# HSM_SOC_CTRL register map
Vendor: Texas Instruments
Peripheral module from a debugger description file (folder awr29xx).
Registers are 32-bit, read-write, no defined reset value unless marked. A register's access mark holds for its fields unless they carry their own. Offsets are as the file gives them; lines under a group give offsets from that group; [hi:lo] are bit positions; {n}, {i} and the like mark numbered series; 'fields as' and 'values as' point back to an identical list; <NAME> marks a mode.

## HSM_SOC_CTRL
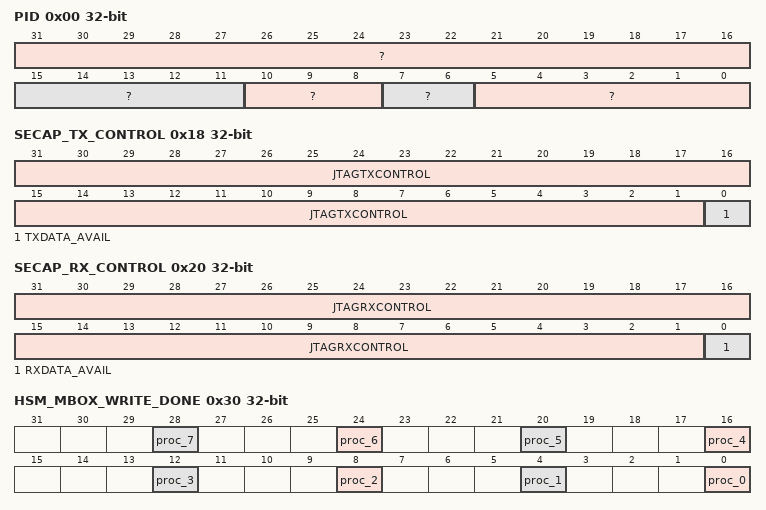
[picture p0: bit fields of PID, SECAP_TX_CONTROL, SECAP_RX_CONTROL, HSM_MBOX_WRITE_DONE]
0x00 PID ro
  [31:16] ?, [15:11] ?, [10:8] ?, [7:6] ?, [5:0] ?
0x04 HW_REG0
  [31:0] hwreg0 — Reserved for HW R&D
0x08 HW_REG1
  [31:0] hwreg1 — Reserved for HW R&D
0x0C PREVIOUS_NAME
  [31:0] hwreg2 — Reserved for HW R&D
0x10 HW_REG3
  [31:0] hwreg3 — Reserved for HW R&D
0x14 SECAP_TX_DATA ro
  [31:0] JTAGTXDATA — This register is used to pass data to the system security logic. The data is transmit from the external JTAG interface and hence is the Rx path for the SECAP interface.
0x18 SECAP_TX_CONTROL ro
  [31:1] JTAGTXCONTROL — This register is provides the handshake for the JTAGTXDATA Register and can also be used to pass control information to the system security logic.
  [0] TXDATA_AVAIL — Tx Interrupt to indicate avaliablity of TXDATA . 1 - TXDATA available ; 0 - TXDATA not available
0x1C SECAP_RX_DATA
  [31:0] JTAGRXDATA — This register is used to pass data from the system security logic. The data is transmit from the SECAP interface to external JTAG interface and hence is the Tx path for the SECAP interface.
0x20 SECAP_RX_CONTROL access per field
  [31:1] JTAGRXCONTROL rw — This register is provides the handshake for the JTAGRXDATA Register and can also be used to pass control information from the system security logic
  [0] RXDATA_AVAIL ro — Tx Interrupt to indicate avaliablity of RXDATA . 1 - RXDATA available ; 0 - RXDATA not available
0x24 HSM_MBOX_MEMINIT_START
  [0] hsm_mbox_meminit_start — Write pulse bit field:#br#Start Memory intialization of Param memory.Write 0x1 to start memory initilization.Write 0x0 after ensuring Memory intilization is in progress or has completed.Before starting new initilzation sequence ensure that there is no initilization sequence is in progress (ie MEMINIT_STATUS should be 0x0) and clear any previouls complettion status(ie write 0x1 to clear MEMINIT_DONE)
0x28 HSM_MBOX_MEMINIT_STATUS ro
  [0] hsm_mbox_meminit_status — Status field. Read value 0x1 indicates previously triggered Memory intialization of Param memory is in progress.
0x2C HSM_MBOX_MEMINIT_DONE
  [0] hsm_mbox_meminit_done — Status field. Read value 0x1 indicates previously triggered Memory intialization of Param memory is complte.#br#Write 0x1 to clear status. Refer Memory initialization sequnce in EDMA section for more details
0x30 HSM_MBOX_WRITE_DONE
  [4n] proc_{n} (n=0..7) — Write pulse bit field:#br#This register should be written once finishing writing into the mailbox memory of processor {n}
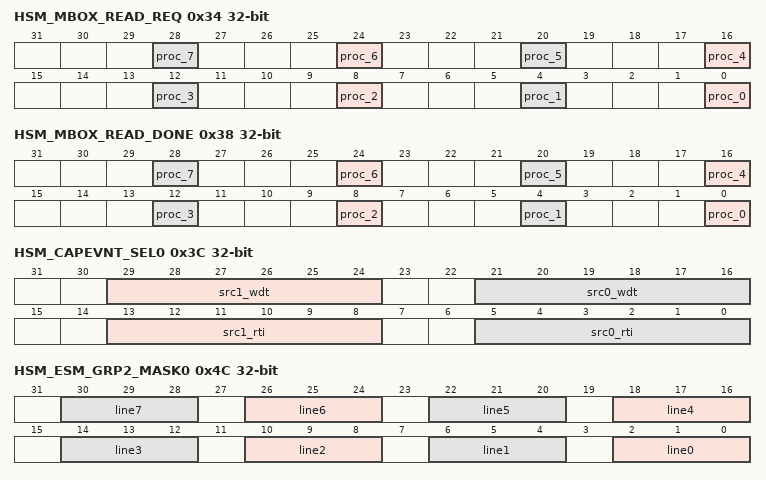
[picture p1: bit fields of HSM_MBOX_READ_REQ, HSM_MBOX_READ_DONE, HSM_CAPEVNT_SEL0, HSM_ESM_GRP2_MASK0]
0x34 HSM_MBOX_READ_REQ
  [4n] proc_{n} (n=0..7) — This is request from processor {n} to HSM. Requesting it to read from mailbox.
0x38 HSM_MBOX_READ_DONE
  [4n] proc_{n} (n=0..7) — This register should be written once finishing reading from hsm's mailbox written by proc {n}
0x3C HSM_CAPEVNT_SEL0
  [29:24] src1_wdt — Used to select one of the 64 interrupts which would go as second trigger to WDT
  [21:16] src0_wdt — Used to select one of the 64 interrupts which would go as first trigger to WDT
  [13:8] src1_rti — Used to select one of the 64 interrupts which would go as second trigger to RTI
  [5:0] src0_rti — Used to select one of the 64 interrupts which would go as first trigger to RTI
0x40 HSM_DMA_REQ
  [2:0] select — Software configration for DMA Request
0x44 HSM_IRQ_REQ
  [3:0] select — Write pulse bit field:#br#Software configration for INT Request
0x48 HSM_ESM_REQ
  [1:0] select — Software configration for ESM Request
0x4C HSM_ESM_GRP2_MASK0
  [4n+2:4n] line{n} (n=0..7) — Writing 3'b111 will un-mask the ESM error for the respective group and line
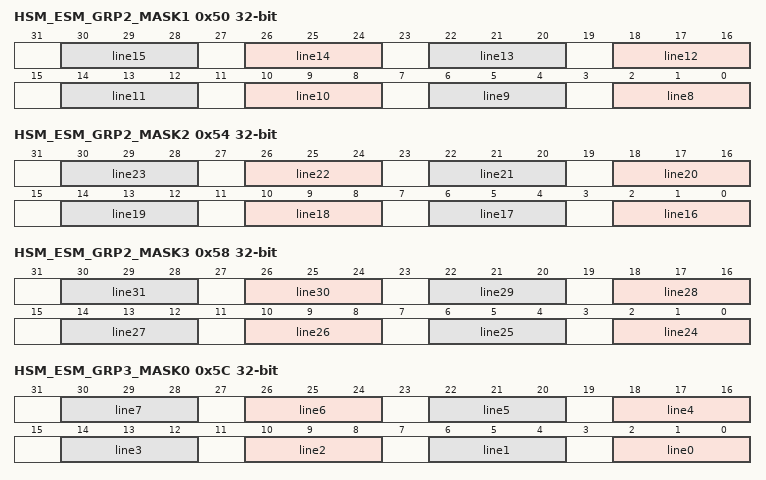
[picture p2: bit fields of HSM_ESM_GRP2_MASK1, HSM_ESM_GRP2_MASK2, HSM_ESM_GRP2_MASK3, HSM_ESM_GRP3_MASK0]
0x50 HSM_ESM_GRP2_MASK1
  [4n-30:4n-32] line{n} (n=8..15) — Writing 3'b111 will un-mask the ESM error for the respective group and line
0x54 HSM_ESM_GRP2_MASK2
  [4n-62:4n-64] line{n} (n=16..23) — Writing 3'b111 will un-mask the ESM error for the respective group and line
0x58 HSM_ESM_GRP2_MASK3
  [4n-94:4n-96] line{n} (n=24..31) — Writing 3'b111 will un-mask the ESM error for the respective group and line
0x5C HSM_ESM_GRP3_MASK0
  fields as HSM_ESM_GRP2_MASK0
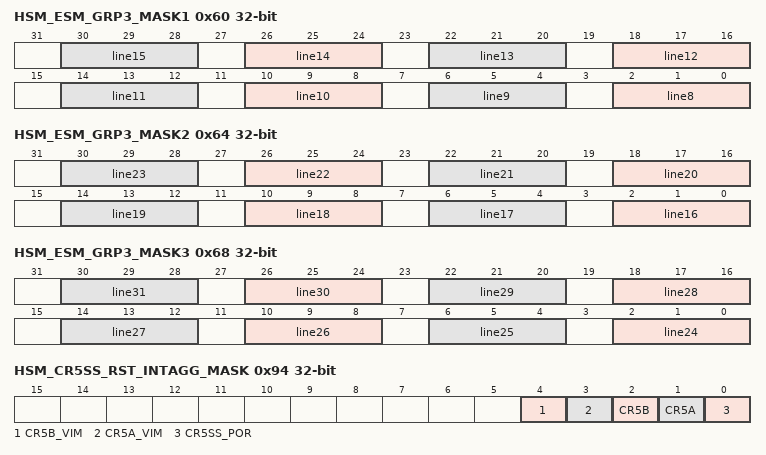
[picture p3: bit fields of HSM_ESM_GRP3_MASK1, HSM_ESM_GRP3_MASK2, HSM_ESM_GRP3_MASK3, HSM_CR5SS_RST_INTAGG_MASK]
0x60 HSM_ESM_GRP3_MASK1
  fields as HSM_ESM_GRP2_MASK1
0x64 HSM_ESM_GRP3_MASK2
  fields as HSM_ESM_GRP2_MASK2
0x68 HSM_ESM_GRP3_MASK3
  fields as HSM_ESM_GRP2_MASK3
0x6C HSM_MSS_RST_CAUSE ro
  [15:0] status — Indicates the Reset Cause of MSS#br#Has the status because of which reset has happened. Bit0: por_reset Bit1: warm reset Bit2: stc reset Bit3: mmr_reset for resetting CPU0 and vim0 Bit4: mmr_reset for resetting CPU1 and VIM1 Bit5: mmr_reset for resettng CPU0 only Bit6: mmr_reset for resetting CPU1 only #br#Bit7: reset caused becasue for dbg_rst_req by CPU0 Bit8: reset caused becasue for dbg_rst_req by CPU0 Bit9: reset caused by the reset_fsm
0x70 HSM_MSS_RST_CAUSE_CLR
  [2:0] clear — Write pulse bit field:#br#Writing '111' will clear the HSM_MSS_RST_CAUSE_STATUS field
{0x74+4i} HSM_SECURE_BOOT_INFO_REG{i} (i=0..7)
  [31:0] reg — Secure Boot Status Registers
0x94 HSM_CR5SS_RST_INTAGG_MASK
  [4] CR5B_VIM — Writing '1' will mask the respective MSS R5SS RST interrupt line
  [3] CR5A_VIM — Writing '1' will mask the respective MSS R5SS RST interrupt line
  [2] CR5B — Writing '1' will mask the respective MSS R5SS RST interrupt line
  [1] CR5A — Writing '1' will mask the respective MSS R5SS RST interrupt line
  [0] CR5SS_POR — Writing '1' will mask the respective MSS R5SS RST interrupt line
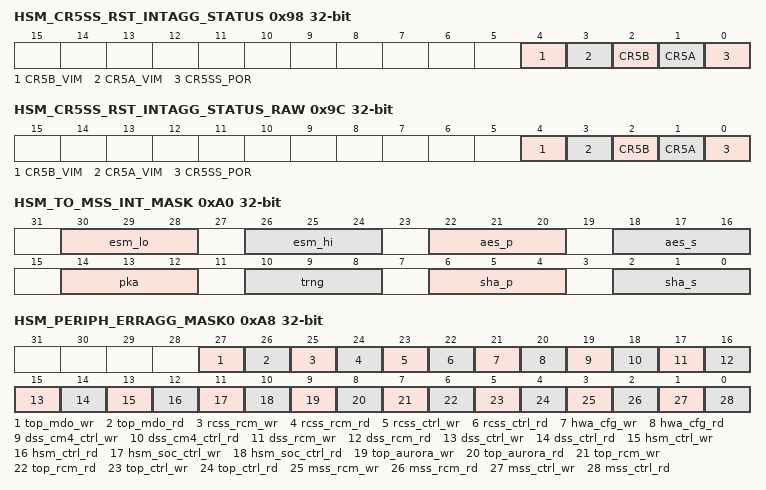
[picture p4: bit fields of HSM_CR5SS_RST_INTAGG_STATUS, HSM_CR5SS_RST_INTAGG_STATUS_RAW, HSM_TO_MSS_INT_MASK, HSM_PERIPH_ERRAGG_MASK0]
0x98 HSM_CR5SS_RST_INTAGG_STATUS
  [4] CR5B_VIM — Indicates the post mask status of the respective MSS R5SS RST interrupt line
  [3] CR5A_VIM — Indicates the post mask status of the respective MSS R5SS RST interrupt line
  [2] CR5B — Indicates the post mask status of the respective MSS R5SS RST interrupt line
  [1] CR5A — Indicates the post mask status of the respective MSS R5SS RST interrupt line
  [0] CR5SS_POR — Indicates the post mask status of the respective MSS R5SS RST interrupt line
0x9C HSM_CR5SS_RST_INTAGG_STATUS_RAW
  [4] CR5B_VIM — Indicates the pre mask status of the respective MSS R5SS RST interrupt line
  [3] CR5A_VIM — Indicates the pre mask status of the respective MSS R5SS RST interrupt line
  [2] CR5B — Indicates the pre mask status of the respective MSS R5SS RST interrupt line
  [1] CR5A — Indicates the pre mask status of the respective MSS R5SS RST interrupt line
  [0] CR5SS_POR — Indicates the pre mask status of the respective MSS R5SS RST interrupt line
0xA0 HSM_TO_MSS_INT_MASK
  [30:28] esm_lo — Writing 3'b111 will un-mask the respective HSM Interrupt line to MSS
  [26:24] esm_hi — Writing 3'b111 will un-mask the respective HSM Interrupt line to MSS
  [22:20] aes_p — Writing 3'b111 will un-mask the respective HSM Interrupt line to MSS
  [18:16] aes_s — Writing 3'b111 will un-mask the respective HSM Interrupt line to MSS
  [14:12] pka — Writing 3'b111 will un-mask the respective HSM Interrupt line to MSS
  [10:8] trng — Writing 3'b111 will un-mask the respective HSM Interrupt line to MSS
  [6:4] sha_p — Writing 3'b111 will un-mask the respective HSM Interrupt line to MSS
  [2:0] sha_s — Writing 3'b111 will un-mask the respective HSM Interrupt line to MSS
0xA4 HSM_WDT_RST_CONFIG
  [2:0] enable — Writing 3'b111 will enable WDT Reset Propogation
0xA8 HSM_PERIPH_ERRAGG_MASK0
  [27] top_mdo_wr — Writing '1' will mask the respective peripheral error line
  [26] top_mdo_rd — Writing '1' will mask the respective peripheral error line
  [25] rcss_rcm_wr — Writing '1' will mask the respective peripheral error line
  [24] rcss_rcm_rd — Writing '1' will mask the respective peripheral error line
  [23] rcss_ctrl_wr — Writing '1' will mask the respective peripheral error line
  [22] rcss_ctrl_rd — Writing '1' will mask the respective peripheral error line
  [21] hwa_cfg_wr — Writing '1' will mask the respective peripheral error line
  [20] hwa_cfg_rd — Writing '1' will mask the respective peripheral error line
  [19] dss_cm4_ctrl_wr — Writing '1' will mask the respective peripheral error line
  [18] dss_cm4_ctrl_rd — Writing '1' will mask the respective peripheral error line
  [17] dss_rcm_wr — Writing '1' will mask the respective peripheral error line
  [16] dss_rcm_rd — Writing '1' will mask the respective peripheral error line
  [15] dss_ctrl_wr — Writing '1' will mask the respective peripheral error line
  [14] dss_ctrl_rd — Writing '1' will mask the respective peripheral error line
  [13] hsm_ctrl_wr — Writing '1' will mask the respective peripheral error line
  [12] hsm_ctrl_rd — Writing '1' will mask the respective peripheral error line
  [11] hsm_soc_ctrl_wr — Writing '1' will mask the respective peripheral error line
  [10] hsm_soc_ctrl_rd — Writing '1' will mask the respective peripheral error line
  [9] top_aurora_wr — Writing '1' will mask the respective peripheral error line
  [8] top_aurora_rd — Writing '1' will mask the respective peripheral error line
  [7] top_rcm_wr — Writing '1' will mask the respective peripheral error line
  [6] top_rcm_rd — Writing '1' will mask the respective peripheral error line
  [5] top_ctrl_wr — Writing '1' will mask the respective peripheral error line
  [4] top_ctrl_rd — Writing '1' will mask the respective peripheral error line
  [3] mss_rcm_wr — Writing '1' will mask the respective peripheral error line
  [2] mss_rcm_rd — Writing '1' will mask the respective peripheral error line
  [1] mss_ctrl_wr — Writing '1' will mask the respective peripheral error line
  [0] mss_ctrl_rd — Writing '1' will mask the respective peripheral error line
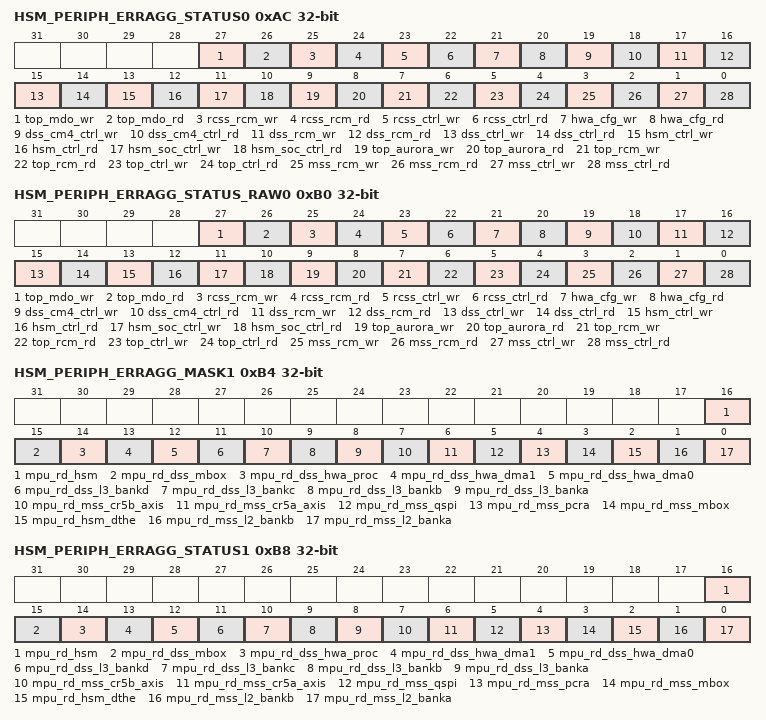
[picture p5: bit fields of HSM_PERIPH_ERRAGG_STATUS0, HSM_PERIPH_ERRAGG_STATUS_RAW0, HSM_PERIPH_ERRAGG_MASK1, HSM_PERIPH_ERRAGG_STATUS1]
0xAC HSM_PERIPH_ERRAGG_STATUS0
  [27] top_mdo_wr — Indicates the post mask status of the respective peripheral error line
  [26] top_mdo_rd — Indicates the post mask status of the respective peripheral error line
  [25] rcss_rcm_wr — Indicates the post mask status of the respective peripheral error line
  [24] rcss_rcm_rd — Indicates the post mask status of the respective peripheral error line
  [23] rcss_ctrl_wr — Indicates the post mask status of the respective peripheral error line
  [22] rcss_ctrl_rd — Indicates the post mask status of the respective peripheral error line
  [21] hwa_cfg_wr — Indicates the post mask status of the respective peripheral error line
  [20] hwa_cfg_rd — Indicates the post mask status of the respective peripheral error line
  [19] dss_cm4_ctrl_wr — Indicates the post mask status of the respective peripheral error line
  [18] dss_cm4_ctrl_rd — Indicates the post mask status of the respective peripheral error line
  [17] dss_rcm_wr — Indicates the post mask status of the respective peripheral error line
  [16] dss_rcm_rd — Indicates the post mask status of the respective peripheral error line
  [15] dss_ctrl_wr — Indicates the post mask status of the respective peripheral error line
  [14] dss_ctrl_rd — Indicates the post mask status of the respective peripheral error line
  [13] hsm_ctrl_wr — Indicates the post mask status of the respective peripheral error line
  [12] hsm_ctrl_rd — Indicates the post mask status of the respective peripheral error line
  [11] hsm_soc_ctrl_wr — Indicates the post mask status of the respective peripheral error line
  [10] hsm_soc_ctrl_rd — Indicates the post mask status of the respective peripheral error line
  [9] top_aurora_wr — Indicates the post mask status of the respective peripheral error line
  [8] top_aurora_rd — Indicates the post mask status of the respective peripheral error line
  [7] top_rcm_wr — Indicates the post mask status of the respective peripheral error line
  [6] top_rcm_rd — Indicates the post mask status of the respective peripheral error line
  [5] top_ctrl_wr — Indicates the post mask status of the respective peripheral error line
  [4] top_ctrl_rd — Indicates the post mask status of the respective peripheral error line
  [3] mss_rcm_wr — Indicates the post mask status of the respective peripheral error line
  [2] mss_rcm_rd — Indicates the post mask status of the respective peripheral error line
  [1] mss_ctrl_wr — Indicates the post mask status of the respective peripheral error line
  [0] mss_ctrl_rd — Indicates the post mask status of the respective peripheral error line
0xB0 HSM_PERIPH_ERRAGG_STATUS_RAW0
  [27] top_mdo_wr — Indicates the pre mask status of the respective peripheral error line
  [26] top_mdo_rd — Indicates the pre mask status of the respective peripheral error line
  [25] rcss_rcm_wr — Indicates the pre mask status of the respective peripheral error line
  [24] rcss_rcm_rd — Indicates the pre mask status of the respective peripheral error line
  [23] rcss_ctrl_wr — Indicates the pre mask status of the respective peripheral error line
  [22] rcss_ctrl_rd — Indicates the pre mask status of the respective peripheral error line
  [21] hwa_cfg_wr — Indicates the pre mask status of the respective peripheral error line
  [20] hwa_cfg_rd — Indicates the pre mask status of the respective peripheral error line
  [19] dss_cm4_ctrl_wr — Indicates the pre mask status of the respective peripheral error line
  [18] dss_cm4_ctrl_rd — Indicates the pre mask status of the respective peripheral error line
  [17] dss_rcm_wr — Indicates the pre mask status of the respective peripheral error line
  [16] dss_rcm_rd — Indicates the pre mask status of the respective peripheral error line
  [15] dss_ctrl_wr — Indicates the pre mask status of the respective peripheral error line
  [14] dss_ctrl_rd — Indicates the pre mask status of the respective peripheral error line
  [13] hsm_ctrl_wr — Indicates the pre mask status of the respective peripheral error line
  [12] hsm_ctrl_rd — Indicates the pre mask status of the respective peripheral error line
  [11] hsm_soc_ctrl_wr — Indicates the pre mask status of the respective peripheral error line
  [10] hsm_soc_ctrl_rd — Indicates the pre mask status of the respective peripheral error line
  [9] top_aurora_wr — Indicates the pre mask status of the respective peripheral error line
  [8] top_aurora_rd — Indicates the pre mask status of the respective peripheral error line
  [7] top_rcm_wr — Indicates the pre mask status of the respective peripheral error line
  [6] top_rcm_rd — Indicates the pre mask status of the respective peripheral error line
  [5] top_ctrl_wr — Indicates the pre mask status of the respective peripheral error line
  [4] top_ctrl_rd — Indicates the pre mask status of the respective peripheral error line
  [3] mss_rcm_wr — Indicates the pre mask status of the respective peripheral error line
  [2] mss_rcm_rd — Indicates the pre mask status of the respective peripheral error line
  [1] mss_ctrl_wr — Indicates the pre mask status of the respective peripheral error line
  [0] mss_ctrl_rd — Indicates the pre mask status of the respective peripheral error line
0xB4 HSM_PERIPH_ERRAGG_MASK1
  [16] mpu_rd_hsm — Writing '1' will mask the respective peripheral error line
  [15] mpu_rd_dss_mbox — Writing '1' will mask the respective peripheral error line
  [14] mpu_rd_dss_hwa_proc — Writing '1' will mask the respective peripheral error line
  [13] mpu_rd_dss_hwa_dma1 — Writing '1' will mask the respective peripheral error line
  [12] mpu_rd_dss_hwa_dma0 — Writing '1' will mask the respective peripheral error line
  [11] mpu_rd_dss_l3_bankd — Writing '1' will mask the respective peripheral error line
  [10] mpu_rd_dss_l3_bankc — Writing '1' will mask the respective peripheral error line
  [9] mpu_rd_dss_l3_bankb — Writing '1' will mask the respective peripheral error line
  [8] mpu_rd_dss_l3_banka — Writing '1' will mask the respective peripheral error line
  [7] mpu_rd_mss_cr5b_axis — Writing '1' will mask the respective peripheral error line
  [6] mpu_rd_mss_cr5a_axis — Writing '1' will mask the respective peripheral error line
  [5] mpu_rd_mss_qspi — Writing '1' will mask the respective peripheral error line
  [4] mpu_rd_mss_pcra — Writing '1' will mask the respective peripheral error line
  [3] mpu_rd_mss_mbox — Writing '1' will mask the respective peripheral error line
  [2] mpu_rd_hsm_dthe — Writing '1' will mask the respective peripheral error line
  [1] mpu_rd_mss_l2_bankb — Writing '1' will mask the respective peripheral error line
  [0] mpu_rd_mss_l2_banka — Writing '1' will mask the respective peripheral error line
0xB8 HSM_PERIPH_ERRAGG_STATUS1
  [16] mpu_rd_hsm — Indicates the post mask status of the respective peripheral error line
  [15] mpu_rd_dss_mbox — Indicates the post mask status of the respective peripheral error line
  [14] mpu_rd_dss_hwa_proc — Indicates the post mask status of the respective peripheral error line
  [13] mpu_rd_dss_hwa_dma1 — Indicates the post mask status of the respective peripheral error line
  [12] mpu_rd_dss_hwa_dma0 — Indicates the post mask status of the respective peripheral error line
  [11] mpu_rd_dss_l3_bankd — Indicates the post mask status of the respective peripheral error line
  [10] mpu_rd_dss_l3_bankc — Indicates the post mask status of the respective peripheral error line
  [9] mpu_rd_dss_l3_bankb — Indicates the post mask status of the respective peripheral error line
  [8] mpu_rd_dss_l3_banka — Indicates the post mask status of the respective peripheral error line
  [7] mpu_rd_mss_cr5b_axis — Indicates the post mask status of the respective peripheral error line
  [6] mpu_rd_mss_cr5a_axis — Indicates the post mask status of the respective peripheral error line
  [5] mpu_rd_mss_qspi — Indicates the post mask status of the respective peripheral error line
  [4] mpu_rd_mss_pcra — Indicates the post mask status of the respective peripheral error line
  [3] mpu_rd_mss_mbox — Indicates the post mask status of the respective peripheral error line
  [2] mpu_rd_hsm_dthe — Indicates the post mask status of the respective peripheral error line
  [1] mpu_rd_mss_l2_bankb — Indicates the post mask status of the respective peripheral error line
  [0] mpu_rd_mss_l2_banka — Indicates the post mask status of the respective peripheral error line
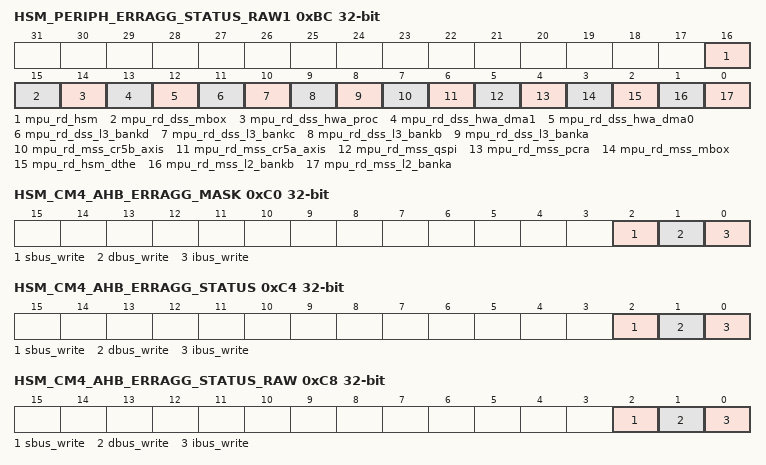
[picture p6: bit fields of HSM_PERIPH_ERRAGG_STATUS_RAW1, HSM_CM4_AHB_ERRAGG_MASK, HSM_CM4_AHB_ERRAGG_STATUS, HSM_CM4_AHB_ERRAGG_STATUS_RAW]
0xBC HSM_PERIPH_ERRAGG_STATUS_RAW1
  [16] mpu_rd_hsm — Indicates the pre mask status of the respective peripheral error line
  [15] mpu_rd_dss_mbox — Indicates the pre mask status of the respective peripheral error line
  [14] mpu_rd_dss_hwa_proc — Indicates the pre mask status of the respective peripheral error line
  [13] mpu_rd_dss_hwa_dma1 — Indicates the pre mask status of the respective peripheral error line
  [12] mpu_rd_dss_hwa_dma0 — Indicates the pre mask status of the respective peripheral error line
  [11] mpu_rd_dss_l3_bankd — Indicates the pre mask status of the respective peripheral error line
  [10] mpu_rd_dss_l3_bankc — Indicates the pre mask status of the respective peripheral error line
  [9] mpu_rd_dss_l3_bankb — Indicates the pre mask status of the respective peripheral error line
  [8] mpu_rd_dss_l3_banka — Indicates the pre mask status of the respective peripheral error line
  [7] mpu_rd_mss_cr5b_axis — Indicates the pre mask status of the respective peripheral error line
  [6] mpu_rd_mss_cr5a_axis — Indicates the pre mask status of the respective peripheral error line
  [5] mpu_rd_mss_qspi — Indicates the pre mask status of the respective peripheral error line
  [4] mpu_rd_mss_pcra — Indicates the pre mask status of the respective peripheral error line
  [3] mpu_rd_mss_mbox — Indicates the pre mask status of the respective peripheral error line
  [2] mpu_rd_hsm_dthe — Indicates the pre mask status of the respective peripheral error line
  [1] mpu_rd_mss_l2_bankb — Indicates the pre mask status of the respective peripheral error line
  [0] mpu_rd_mss_l2_banka — Indicates the pre mask status of the respective peripheral error line
0xC0 HSM_CM4_AHB_ERRAGG_MASK
  [2] sbus_write — Writing '1' will mask the respective peripheral error line
  [1] dbus_write — Writing '1' will mask the respective peripheral error line
  [0] ibus_write — Writing '1' will mask the respective peripheral error line
0xC4 HSM_CM4_AHB_ERRAGG_STATUS
  [2] sbus_write — Indicates the post mask status of the respective peripheral error line
  [1] dbus_write — Indicates the post mask status of the respective peripheral error line
  [0] ibus_write — Indicates the post mask status of the respective peripheral error line
0xC8 HSM_CM4_AHB_ERRAGG_STATUS_RAW
  [2] sbus_write — Indicates the pre mask status of the respective peripheral error line
  [1] dbus_write — Indicates the pre mask status of the respective peripheral error line
  [0] ibus_write — Indicates the pre mask status of the respective peripheral error line
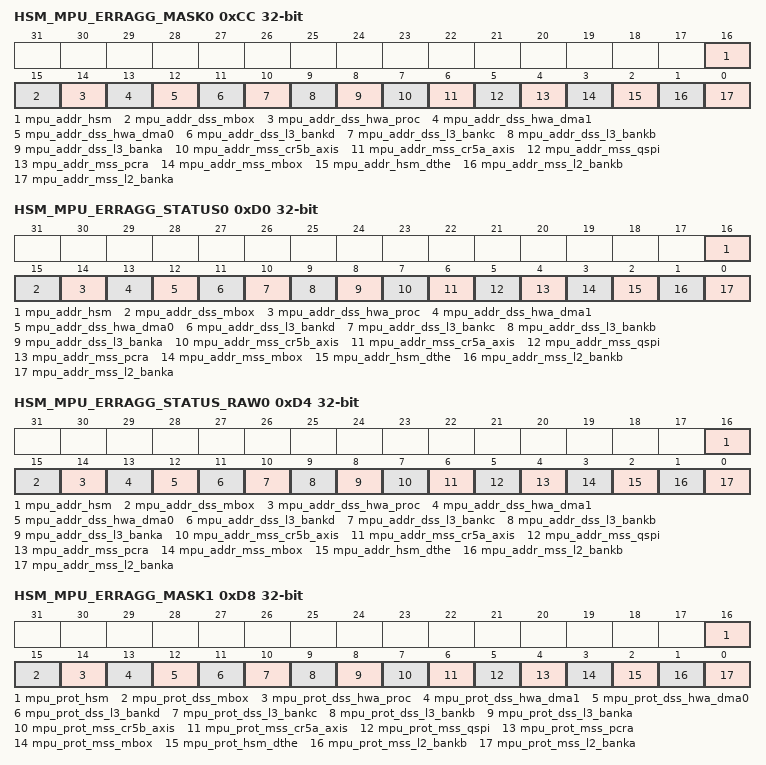
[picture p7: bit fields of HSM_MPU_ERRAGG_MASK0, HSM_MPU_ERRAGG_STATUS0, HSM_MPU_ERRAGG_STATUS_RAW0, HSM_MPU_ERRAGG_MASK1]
0xCC HSM_MPU_ERRAGG_MASK0
  [16] mpu_addr_hsm — Writing '1' will mask the respective MPU address error line
  [15] mpu_addr_dss_mbox — Writing '1' will mask the respective MPU address error line
  [14] mpu_addr_dss_hwa_proc — Writing '1' will mask the respective MPU address error line
  [13] mpu_addr_dss_hwa_dma1 — Writing '1' will mask the respective MPU address error line
  [12] mpu_addr_dss_hwa_dma0 — Writing '1' will mask the respective MPU address error line
  [11] mpu_addr_dss_l3_bankd — Writing '1' will mask the respective MPU address error line
  [10] mpu_addr_dss_l3_bankc — Writing '1' will mask the respective MPU address error line
  [9] mpu_addr_dss_l3_bankb — Writing '1' will mask the respective MPU address error line
  [8] mpu_addr_dss_l3_banka — Writing '1' will mask the respective MPU address error line
  [7] mpu_addr_mss_cr5b_axis — Writing '1' will mask the respective MPU address error line
  [6] mpu_addr_mss_cr5a_axis — Writing '1' will mask the respective MPU address error line
  [5] mpu_addr_mss_qspi — Writing '1' will mask the respective MPU address error line
  [4] mpu_addr_mss_pcra — Writing '1' will mask the respective MPU address error line
  [3] mpu_addr_mss_mbox — Writing '1' will mask the respective MPU address error line
  [2] mpu_addr_hsm_dthe — Writing '1' will mask the respective MPU address error line
  [1] mpu_addr_mss_l2_bankb — Writing '1' will mask the respective MPU address error line
  [0] mpu_addr_mss_l2_banka — Writing '1' will mask the respective MPU address error line
0xD0 HSM_MPU_ERRAGG_STATUS0
  [16] mpu_addr_hsm — Indicates the post mask status of the respective MPU address error line
  [15] mpu_addr_dss_mbox — Indicates the post mask status of the respective MPU address error line
  [14] mpu_addr_dss_hwa_proc — Indicates the post mask status of the respective MPU address error line
  [13] mpu_addr_dss_hwa_dma1 — Indicates the post mask status of the respective MPU address error line
  [12] mpu_addr_dss_hwa_dma0 — Indicates the post mask status of the respective MPU address error line
  [11] mpu_addr_dss_l3_bankd — Indicates the post mask status of the respective MPU address error line
  [10] mpu_addr_dss_l3_bankc — Indicates the post mask status of the respective MPU address error line
  [9] mpu_addr_dss_l3_bankb — Indicates the post mask status of the respective MPU address error line
  [8] mpu_addr_dss_l3_banka — Indicates the post mask status of the respective MPU address error line
  [7] mpu_addr_mss_cr5b_axis — Indicates the post mask status of the respective MPU address error line
  [6] mpu_addr_mss_cr5a_axis — Indicates the post mask status of the respective MPU address error line
  [5] mpu_addr_mss_qspi — Indicates the post mask status of the respective MPU address error line
  [4] mpu_addr_mss_pcra — Indicates the post mask status of the respective MPU address error line
  [3] mpu_addr_mss_mbox — Indicates the post mask status of the respective MPU address error line
  [2] mpu_addr_hsm_dthe — Indicates the post mask status of the respective MPU address error line
  [1] mpu_addr_mss_l2_bankb — Indicates the post mask status of the respective MPU address error line
  [0] mpu_addr_mss_l2_banka — Indicates the post mask status of the respective MPU address error line
0xD4 HSM_MPU_ERRAGG_STATUS_RAW0
  [16] mpu_addr_hsm — Indicates the pre mask status of the respective MPU address error line
  [15] mpu_addr_dss_mbox — Indicates the pre mask status of the respective MPU address error line
  [14] mpu_addr_dss_hwa_proc — Indicates the pre mask status of the respective MPU address error line
  [13] mpu_addr_dss_hwa_dma1 — Indicates the pre mask status of the respective MPU address error line
  [12] mpu_addr_dss_hwa_dma0 — Indicates the pre mask status of the respective MPU address error line
  [11] mpu_addr_dss_l3_bankd — Indicates the pre mask status of the respective MPU address error line
  [10] mpu_addr_dss_l3_bankc — Indicates the pre mask status of the respective MPU address error line
  [9] mpu_addr_dss_l3_bankb — Indicates the pre mask status of the respective MPU address error line
  [8] mpu_addr_dss_l3_banka — Indicates the pre mask status of the respective MPU address error line
  [7] mpu_addr_mss_cr5b_axis — Indicates the pre mask status of the respective MPU address error line
  [6] mpu_addr_mss_cr5a_axis — Indicates the pre mask status of the respective MPU address error line
  [5] mpu_addr_mss_qspi — Indicates the pre mask status of the respective MPU address error line
  [4] mpu_addr_mss_pcra — Indicates the pre mask status of the respective MPU address error line
  [3] mpu_addr_mss_mbox — Indicates the pre mask status of the respective MPU address error line
  [2] mpu_addr_hsm_dthe — Indicates the pre mask status of the respective MPU address error line
  [1] mpu_addr_mss_l2_bankb — Indicates the pre mask status of the respective MPU address error line
  [0] mpu_addr_mss_l2_banka — Indicates the pre mask status of the respective MPU address error line
0xD8 HSM_MPU_ERRAGG_MASK1
  [16] mpu_prot_hsm — Writing '1' will mask the respective MPU protection error line
  [15] mpu_prot_dss_mbox — Writing '1' will mask the respective MPU protection error line
  [14] mpu_prot_dss_hwa_proc — Writing '1' will mask the respective MPU protection error line
  [13] mpu_prot_dss_hwa_dma1 — Writing '1' will mask the respective MPU protection error line
  [12] mpu_prot_dss_hwa_dma0 — Writing '1' will mask the respective MPU protection error line
  [11] mpu_prot_dss_l3_bankd — Writing '1' will mask the respective MPU protection error line
  [10] mpu_prot_dss_l3_bankc — Writing '1' will mask the respective MPU protection error line
  [9] mpu_prot_dss_l3_bankb — Writing '1' will mask the respective MPU protection error line
  [8] mpu_prot_dss_l3_banka — Writing '1' will mask the respective MPU protection error line
  [7] mpu_prot_mss_cr5b_axis — Writing '1' will mask the respective MPU protection error line
  [6] mpu_prot_mss_cr5a_axis — Writing '1' will mask the respective MPU protection error line
  [5] mpu_prot_mss_qspi — Writing '1' will mask the respective MPU protection error line
  [4] mpu_prot_mss_pcra — Writing '1' will mask the respective MPU protection error line
  [3] mpu_prot_mss_mbox — Writing '1' will mask the respective MPU protection error line
  [2] mpu_prot_hsm_dthe — Writing '1' will mask the respective MPU protection error line
  [1] mpu_prot_mss_l2_bankb — Writing '1' will mask the respective MPU protection error line
  [0] mpu_prot_mss_l2_banka — Writing '1' will mask the respective MPU protection error line
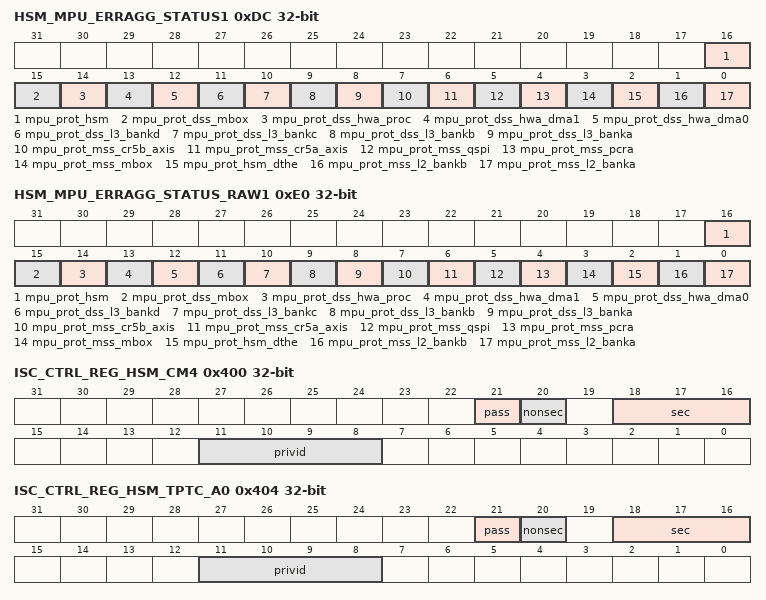
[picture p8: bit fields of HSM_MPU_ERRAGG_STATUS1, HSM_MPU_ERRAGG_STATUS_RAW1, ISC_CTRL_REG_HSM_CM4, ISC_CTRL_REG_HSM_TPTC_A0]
0xDC HSM_MPU_ERRAGG_STATUS1
  [16] mpu_prot_hsm — Indicates the post mask status of the respective MPU protection error line
  [15] mpu_prot_dss_mbox — Indicates the post mask status of the respective MPU protection error line
  [14] mpu_prot_dss_hwa_proc — Indicates the post mask status of the respective MPU protection error line
  [13] mpu_prot_dss_hwa_dma1 — Indicates the post mask status of the respective MPU protection error line
  [12] mpu_prot_dss_hwa_dma0 — Indicates the post mask status of the respective MPU protection error line
  [11] mpu_prot_dss_l3_bankd — Indicates the post mask status of the respective MPU protection error line
  [10] mpu_prot_dss_l3_bankc — Indicates the post mask status of the respective MPU protection error line
  [9] mpu_prot_dss_l3_bankb — Indicates the post mask status of the respective MPU protection error line
  [8] mpu_prot_dss_l3_banka — Indicates the post mask status of the respective MPU protection error line
  [7] mpu_prot_mss_cr5b_axis — Indicates the post mask status of the respective MPU protection error line
  [6] mpu_prot_mss_cr5a_axis — Indicates the post mask status of the respective MPU protection error line
  [5] mpu_prot_mss_qspi — Indicates the post mask status of the respective MPU protection error line
  [4] mpu_prot_mss_pcra — Indicates the post mask status of the respective MPU protection error line
  [3] mpu_prot_mss_mbox — Indicates the post mask status of the respective MPU protection error line
  [2] mpu_prot_hsm_dthe — Indicates the post mask status of the respective MPU protection error line
  [1] mpu_prot_mss_l2_bankb — Indicates the post mask status of the respective MPU protection error line
  [0] mpu_prot_mss_l2_banka — Indicates the post mask status of the respective MPU protection error line
0xE0 HSM_MPU_ERRAGG_STATUS_RAW1
  [16] mpu_prot_hsm — Indicates the pre mask status of the respective MPU protection error line
  [15] mpu_prot_dss_mbox — Indicates the pre mask status of the respective MPU protection error line
  [14] mpu_prot_dss_hwa_proc — Indicates the pre mask status of the respective MPU protection error line
  [13] mpu_prot_dss_hwa_dma1 — Indicates the pre mask status of the respective MPU protection error line
  [12] mpu_prot_dss_hwa_dma0 — Indicates the pre mask status of the respective MPU protection error line
  [11] mpu_prot_dss_l3_bankd — Indicates the pre mask status of the respective MPU protection error line
  [10] mpu_prot_dss_l3_bankc — Indicates the pre mask status of the respective MPU protection error line
  [9] mpu_prot_dss_l3_bankb — Indicates the pre mask status of the respective MPU protection error line
  [8] mpu_prot_dss_l3_banka — Indicates the pre mask status of the respective MPU protection error line
  [7] mpu_prot_mss_cr5b_axis — Indicates the pre mask status of the respective MPU protection error line
  [6] mpu_prot_mss_cr5a_axis — Indicates the pre mask status of the respective MPU protection error line
  [5] mpu_prot_mss_qspi — Indicates the pre mask status of the respective MPU protection error line
  [4] mpu_prot_mss_pcra — Indicates the pre mask status of the respective MPU protection error line
  [3] mpu_prot_mss_mbox — Indicates the pre mask status of the respective MPU protection error line
  [2] mpu_prot_hsm_dthe — Indicates the pre mask status of the respective MPU protection error line
  [1] mpu_prot_mss_l2_bankb — Indicates the pre mask status of the respective MPU protection error line
  [0] mpu_prot_mss_l2_banka — Indicates the pre mask status of the respective MPU protection error line
0x400 ISC_CTRL_REG_HSM_CM4
  [21] pass — No privID replacement. A value of 1 will pass through privid value. A value of 0 will replace privid with priv_id field value
  [20] nonsec — Make outgoing non-secure. A value of 1 forces secure clear, others do nothing. Do not set both sec and nonsec.
  [18:16] sec — Make outgoing secure. A value of 3'b111 forces secure set, others do nothing. Do not set both sec and nonsec.
  [11:8] privid — Privilidge ID configuration
0x404 ISC_CTRL_REG_HSM_TPTC_A0
  fields as ISC_CTRL_REG_HSM_CM4
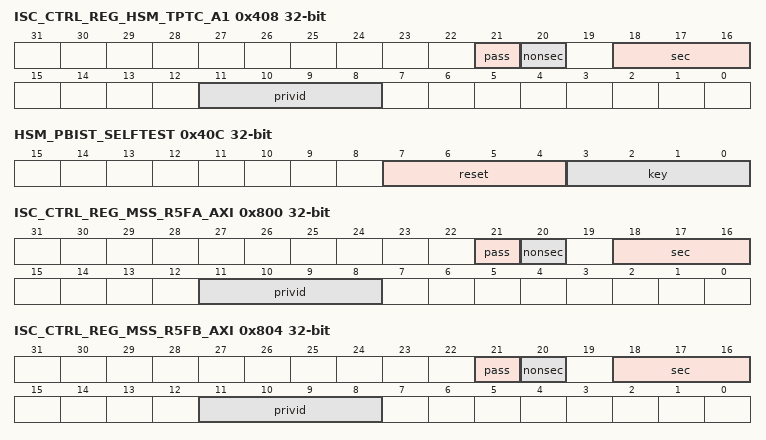
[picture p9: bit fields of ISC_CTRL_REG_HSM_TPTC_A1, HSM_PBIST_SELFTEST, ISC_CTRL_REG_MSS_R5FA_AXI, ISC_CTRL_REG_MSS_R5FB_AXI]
0x408 ISC_CTRL_REG_HSM_TPTC_A1
  fields as ISC_CTRL_REG_HSM_CM4
0x40C HSM_PBIST_SELFTEST
  [7:4] reset — HSM PBIST controller will be reset when value is 0xA
  [3:0] key — HSM PBIST Selftest Key. Valid value is 0x5
0x800 ISC_CTRL_REG_MSS_R5FA_AXI
  fields as ISC_CTRL_REG_HSM_CM4
0x804 ISC_CTRL_REG_MSS_R5FB_AXI
  fields as ISC_CTRL_REG_HSM_CM4
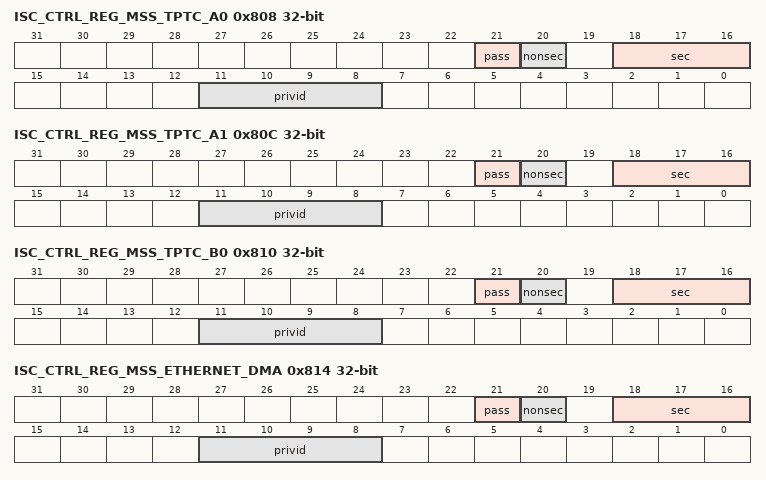
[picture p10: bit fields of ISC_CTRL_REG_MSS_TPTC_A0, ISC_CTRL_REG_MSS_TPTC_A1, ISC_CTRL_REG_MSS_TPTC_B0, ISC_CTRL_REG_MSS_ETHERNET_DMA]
0x808 ISC_CTRL_REG_MSS_TPTC_A0
  fields as ISC_CTRL_REG_HSM_CM4
0x80C ISC_CTRL_REG_MSS_TPTC_A1
  fields as ISC_CTRL_REG_HSM_CM4
0x810 ISC_CTRL_REG_MSS_TPTC_B0
  fields as ISC_CTRL_REG_HSM_CM4
0x814 ISC_CTRL_REG_MSS_ETHERNET_DMA
  fields as ISC_CTRL_REG_HSM_CM4
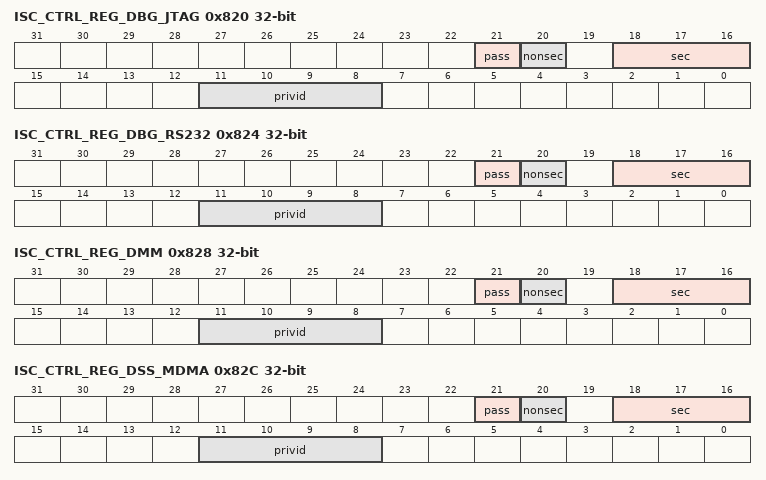
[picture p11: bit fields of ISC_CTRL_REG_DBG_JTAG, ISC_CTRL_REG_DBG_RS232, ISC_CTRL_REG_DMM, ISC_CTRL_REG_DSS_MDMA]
0x820 ISC_CTRL_REG_DBG_JTAG
  fields as ISC_CTRL_REG_HSM_CM4
0x824 ISC_CTRL_REG_DBG_RS232
  fields as ISC_CTRL_REG_HSM_CM4
0x828 ISC_CTRL_REG_DMM
  fields as ISC_CTRL_REG_HSM_CM4
0x82C ISC_CTRL_REG_DSS_MDMA
  fields as ISC_CTRL_REG_HSM_CM4
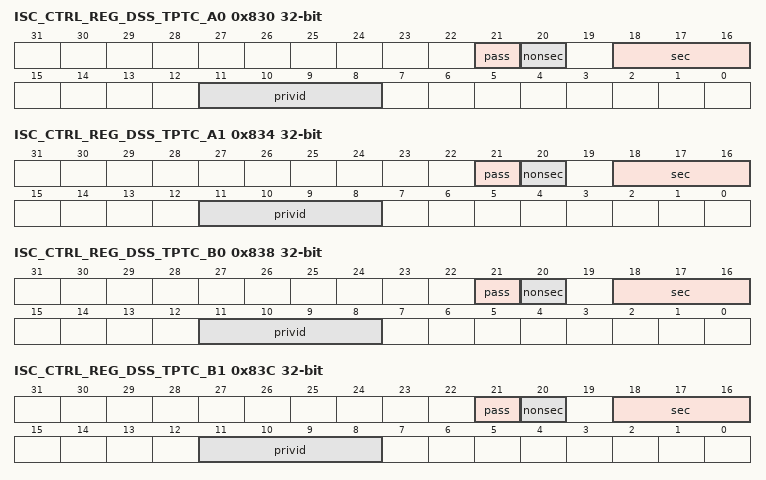
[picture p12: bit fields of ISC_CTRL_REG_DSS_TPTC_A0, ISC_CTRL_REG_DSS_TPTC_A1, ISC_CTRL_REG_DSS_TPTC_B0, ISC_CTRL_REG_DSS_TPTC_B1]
0x830 ISC_CTRL_REG_DSS_TPTC_A0
  fields as ISC_CTRL_REG_HSM_CM4
0x834 ISC_CTRL_REG_DSS_TPTC_A1
  fields as ISC_CTRL_REG_HSM_CM4
0x838 ISC_CTRL_REG_DSS_TPTC_B0
  fields as ISC_CTRL_REG_HSM_CM4
0x83C ISC_CTRL_REG_DSS_TPTC_B1
  fields as ISC_CTRL_REG_HSM_CM4
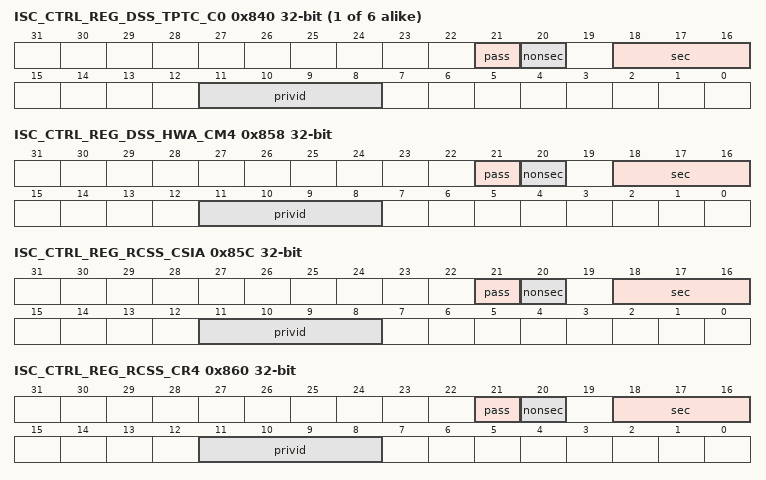
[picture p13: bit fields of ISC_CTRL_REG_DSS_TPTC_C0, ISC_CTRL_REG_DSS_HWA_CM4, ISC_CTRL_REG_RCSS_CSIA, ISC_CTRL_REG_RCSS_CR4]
{0x840+4i} ISC_CTRL_REG_DSS_TPTC_C{i} (i=0..5)
  fields as ISC_CTRL_REG_HSM_CM4
0x858 ISC_CTRL_REG_DSS_HWA_CM4
  fields as ISC_CTRL_REG_HSM_CM4
0x85C ISC_CTRL_REG_RCSS_CSIA
  fields as ISC_CTRL_REG_HSM_CM4
0x860 ISC_CTRL_REG_RCSS_CR4
  fields as ISC_CTRL_REG_HSM_CM4
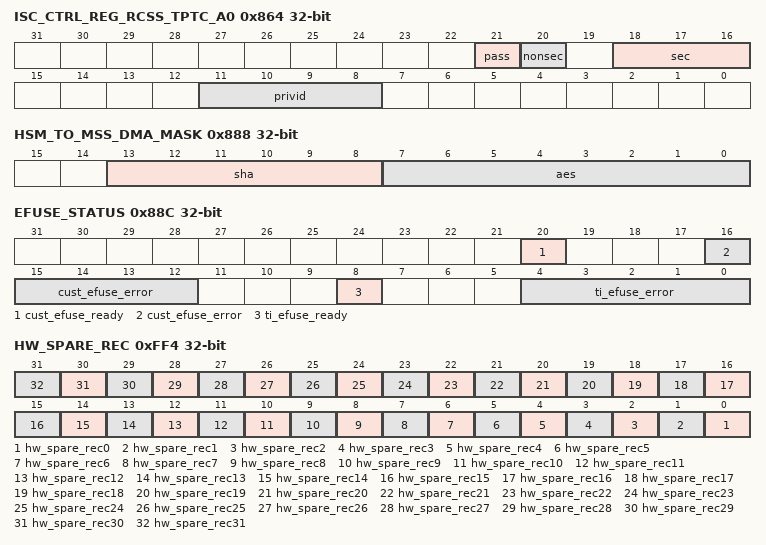
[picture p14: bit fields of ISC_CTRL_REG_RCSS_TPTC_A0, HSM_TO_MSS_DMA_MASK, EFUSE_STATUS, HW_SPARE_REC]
0x864 ISC_CTRL_REG_RCSS_TPTC_A0
  fields as ISC_CTRL_REG_HSM_CM4
0x874 DBG_MASTERS_PRIVID_OVERRIDE
  [0] enable — Debug Masters (DBG_JTAG, DBG_RS232, DMM) Privid Override. A value of '1b1 will override the hardware tie-off privid and provide control to respective ISC register, in case of EMU device and HS-FS, SOP1,2,3.
0x878 HSM_RTC_CFG_CTRL
  [0] counter_read_enable — Write pulse bit field: Reserved for HW R&D
0x87C HSM_RTC_CFG_STATUS ro
  [0] read_valid — Reserved for HW R&D
0x880 HSM_RTC_MSB_COUNTER ro
  [31:0] value — RTC Counter Value - MSB Bits [63:32]
0x884 HSM_RTC_LSB_COUNTER ro
  [31:0] value — RTC Counter Value - LSB Bits [31:0]
0x888 HSM_TO_MSS_DMA_MASK
  [13:8] sha — Writing 1'b1 will un-mask the respective HSM DMA line to MSS
  [7:0] aes — Writing 1'b1 will un-mask the respective HSM DMA line to MSS
0x88C EFUSE_STATUS ro
  [20] cust_efuse_ready, [16:12] cust_efuse_error, [8] ti_efuse_ready, [4:0] ti_efuse_error
{0xFD0+4i} HW_SPARE_RW{i} (i=0..3)
  [31:0] hw_spare_rw{i} — Reserved for HW R&D
{0xFE0+4i} HW_SPARE_RO{i} ro (i=0..3)
  [31:0] hw_spare_ro{i} — Reserved for HW R&D
0xFF0 HW_SPARE_WPH
  [31:0] proc — Write pulse bit field:#br#For bits 0 to 7:#br#Wrting#br#1'b1 : Generates pulse interrupt to corresponding proc from HSM CM4.
0xFF4 HW_SPARE_REC
  [n] hw_spare_rec{n} (n=0..31) — Reserved for HW R&D
0x1008 LOCK0_KICK0 — - KICK0 component
  [31:0] ?
0x100C LOCK0_KICK1 — - KICK1 component
  [31:0] ?
0x1010 intr_raw_status — Interrupt Raw Status/Set Register
  [3] ? — Proxy0 access violation error. Raw status is read. Write a 1 to set the status. Writing a 0 has no effect.
  [2] ? — Kick access violation error. Raw status is read. Write a 1 to set the status. Writing a 0 has no effect.
  [1] ? — Addressing violation error. Raw status is read. Write a 1 to set the status. Writing a 0 has no effect.
  [0] ? — Protection violation error. Raw status is read. Write a 1 to set the status. Writing a 0 has no effect.
0x1014 intr_enabled_status_clear — Interrupt Enabled Status/Clear register
  [3] ? — Proxy0 access violation error. Enabled status is read. Write a 1 to clear the status. Writing a 0 has no effect.
  [2] ? — Kick access violation error. Enabled status is read. Write a 1 to clear the status. Writing a 0 has no effect.
  [1] ? — Addressing violation error. Enabled status is read. Write a 1 to clear the status. Writing a 0 has no effect.
  [0] ? — Protection violation error. Enabled status is read. Write a 1 to clear the status. Writing a 0 has no effect.
0x1018 intr_enable — Interrupt Enable register
  [3] ? — Proxy0 access violation error enable. Write a 1 to set the enable. Writing a 0 has no effect.
  [2] ? — Kick access violation error enable. Write a 1 to set the enable. Writing a 0 has no effect.
  [1] ? — Addressing violation error enable. Write a 1 to set the enable. Writing a 0 has no effect.
  [0] ? — Protection violation error enable. Write a 1 to set the enable. Writing a 0 has no effect.
0x101C intr_enable_clear — Interrupt Enable Clear register
  [3] ? — Proxy0 access violation error enable clear. Write a 1 to clear the enable. Writing a 0 has no effect.
  [2] ? — Kick access violation error enable clear. Write a 1 to clear the enable. Writing a 0 has no effect.
  [1] ? — Addressing violation error enable clear. Write a 1 to clear the enable. Writing a 0 has no effect.
  [0] ? — Protection violation error enable clear. Write a 1 to clear the enable. Writing a 0 has no effect.
0x1020 eoi
  [7:0] ? — EOI vector value. Write this with interrupt distribution value in the chip.
0x1024 fault_address ro
  [31:0] ? — Fault Address.
0x1028 fault_type_status ro
  [6] ? — Non-secure access.
  [5:0] ? — Fault Type #br# 10_0000 = Supervisor read fault - priv = 1 dir = 1 dtype != 1 #br# 01_0000 = Supervisor write fault - priv = 1 dir = 0 #br# 00_1000 = Supervisor execute fault - priv = 1 dir = 1 dtype = 1 #br# 00_0100 = User read fault - priv = 0 dir = 1 dtype = 1 #br# 00_0010 = User write fault - priv = 0 dir = 0 #br# 00_0001 = User execute fault - priv = 0 dir = 1 dtype = 1 #br# 00_0000 = No fault
0x102C fault_attr_status ro — Fault Attribute Status register
  [31:20] ? — XID.
  [19:8] ? — Route ID.
  [7:0] ? — Privilege ID.
0x1030 fault_clear wo
  [0] ? — Fault clear. Writing a 1 clears the current fault. Writing a 0 has no effect.
